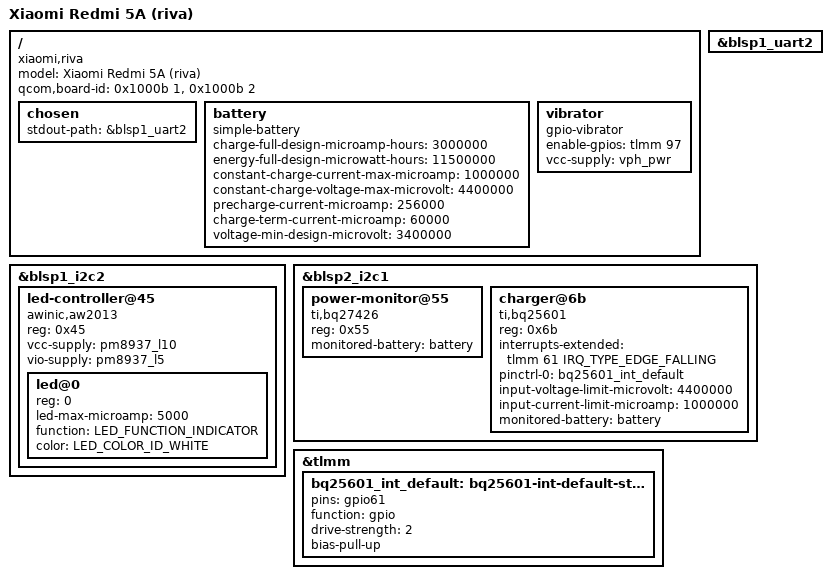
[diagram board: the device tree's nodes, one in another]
// SPDX-License-Identifier: GPL-2.0-only
/*
 * Copyright (c) 2023, Barnabas Czeman
 */

/dts-v1/;

#include <dt-bindings/leds/common.h>
#include "msm8917-xiaomi-wingtech.dtsi"

/ {
	model = "Xiaomi Redmi 5A (riva)";
	compatible = "xiaomi,riva", "qcom,msm8917";

	qcom,board-id = <0x1000b 1>, <0x1000b 2>;

	chosen {
		stdout-path = &blsp1_uart2;
	};

	battery: battery {
		compatible = "simple-battery";
		charge-full-design-microamp-hours = <3000000>;
		energy-full-design-microwatt-hours = <11500000>;
		constant-charge-current-max-microamp = <1000000>;
		constant-charge-voltage-max-microvolt = <4400000>;
		precharge-current-microamp = <256000>;
		charge-term-current-microamp = <60000>;
		voltage-min-design-microvolt = <3400000>;
	};

	vibrator {
		compatible = "gpio-vibrator";
		enable-gpios = <&tlmm 97 GPIO_ACTIVE_HIGH>;
		vcc-supply = <&vph_pwr>;
	};
};

&blsp1_i2c2 {
	status = "okay";

	led-controller@45 {
		compatible = "awinic,aw2013";
		reg = <0x45>;
		vcc-supply = <&pm8937_l10>;
		vio-supply = <&pm8937_l5>;
		#address-cells = <1>;
		#size-cells = <0>;

		led@0 {
			reg = <0>;
			led-max-microamp = <5000>;
			function = LED_FUNCTION_INDICATOR;
			color = <LED_COLOR_ID_WHITE>;
		};
	};
};

&blsp1_uart2 {
	status = "okay";
};

&blsp2_i2c1 {
	status = "okay";

	power-monitor@55 {
		compatible = "ti,bq27426";
		reg = <0x55>;
		monitored-battery = <&battery>;
	};

	charger@6b {
		compatible = "ti,bq25601";
		reg = <0x6b>;
		interrupts-extended = <&tlmm 61 IRQ_TYPE_EDGE_FALLING>;
		pinctrl-0 = <&bq25601_int_default>;
		pinctrl-names = "default";
		input-voltage-limit-microvolt = <4400000>;
		input-current-limit-microamp = <1000000>;
		monitored-battery = <&battery>;
	};
};

&tlmm {
	bq25601_int_default: bq25601-int-default-state {
		pins = "gpio61";
		function = "gpio";
		drive-strength = <2>;
		bias-pull-up;
	};
};
